# MM32SPIN0230 register map
Series: ARM Cortex M0; File version: 1.0
CPU: CM0 r0p0, little endian, no MPU, no FPU, 2 interrupt priority bits
Registers are 32-bit, read-write, reset 0x0 unless marked. A register's access mark holds for its fields unless they carry their own. Offsets are from the block's base; [hi:lo] are bit positions; {n}, {i} and the like mark numbered series.

## HWDIV
Base 0x40030000
0x00 DVDR — Dividend register
  [31:0] DIVIDEND
0x04 DVSR reset 0x1 — Divisor register
  [31:0] DIVISOR
0x08 QUOTR ro — Quotient register
  [31:0] QUOTIENT
0x0C RMDR ro — Remainder register
  [31:0] REMAINDER
0x10 SR ro — Status register
  [0] OVF
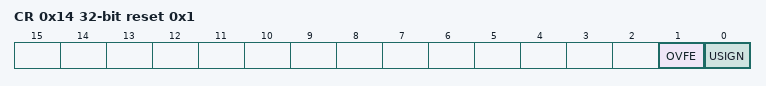
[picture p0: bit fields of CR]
0x14 CR reset 0x1 — Control register
  [1] OVFE, [0] USIGN

## IWDG
Base 0x40003000
0x00 KR wo — Key register
  [15:0] KEY
0x04 PR — Prescaler register
  [2:0] PR
0x08 RLR reset 0xFFF — Reload register
  [11:0] RL
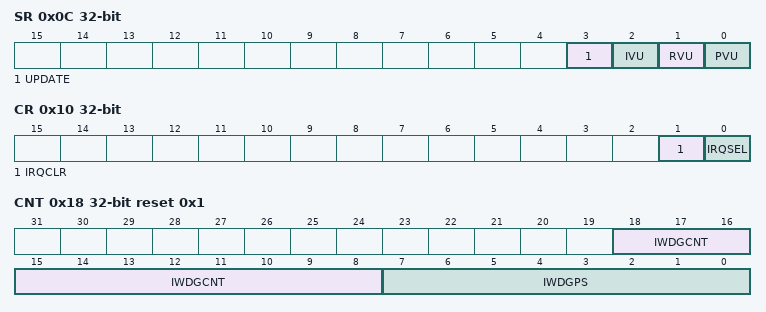
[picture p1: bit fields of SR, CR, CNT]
0x0C SR ro — Status register
  [3] UPDATE, [2] IVU, [1] RVU, [0] PVU
0x10 CR — Control register
  [1] IRQCLR, [0] IRQSEL
0x14 IGEN reset 0xFFF — Interrupt generate register
  [11:0] IGEN
0x18 CNT ro reset 0x1 — Counter register
  [18:8] IWDGCNT, [7:0] IWDGPS

## OPAMP1
Base 0x40009000
Same registers: OPAMP2 0x40009400
0x00 CR reset 0x2 — Configuration register
  [0] OPAEN

## PWR
Base 0x40007000
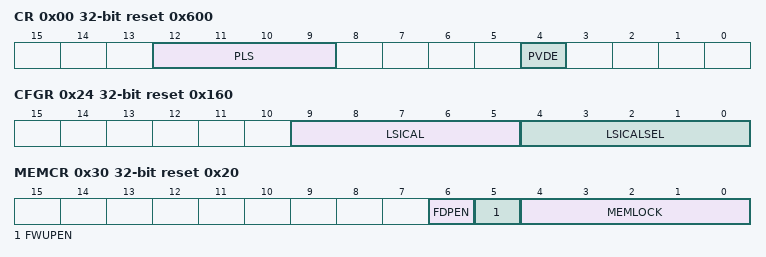
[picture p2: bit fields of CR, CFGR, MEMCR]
0x00 CR reset 0x600 — Power control register
  [12:9] PLS, [4] PVDE
0x04 CSR ro — Power control status register
  [2] PVDO
0x24 CFGR reset 0x160 — Power configuration register
  [9:5] LSICAL, [4:0] LSICALSEL wo
0x30 MEMCR reset 0x20 — Power memory control register
  [6] FDPEN, [5] FWUPEN, [4:0] MEMLOCK wo

## RCC
Base 0x40021000
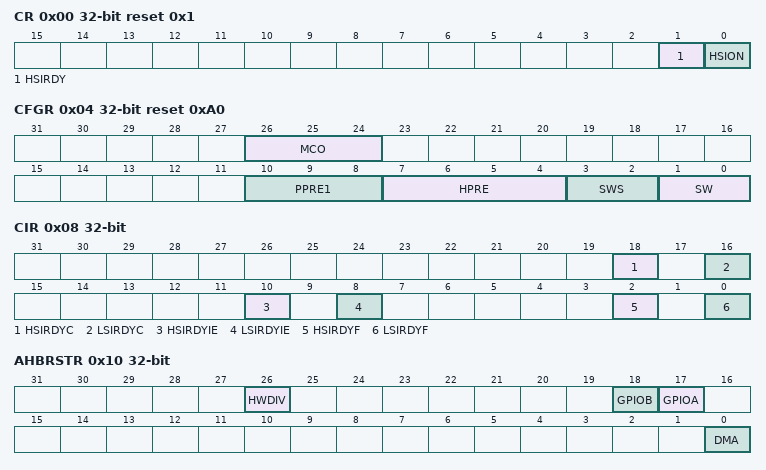
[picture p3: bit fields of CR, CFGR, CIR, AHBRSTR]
0x00 CR reset 0x1 — RCC control register
  [1] HSIRDY ro, [0] HSION
0x04 CFGR reset 0xA0 — RCC configuration register
  [26:24] MCO, [10:8] PPRE1, [7:4] HPRE, [3:2] SWS ro, [1:0] SW
0x08 CIR — RCC clock interrupt register
  [18] HSIRDYC write-1-clears, [16] LSIRDYC write-1-clears, [10] HSIRDYIE, [8] LSIRDYIE, [2] HSIRDYF ro, [0] LSIRDYF ro
0x10 AHBRSTR — RCC AHB peripheral reset register
  [26] HWDIV, [18] GPIOB, [17] GPIOA, [0] DMA
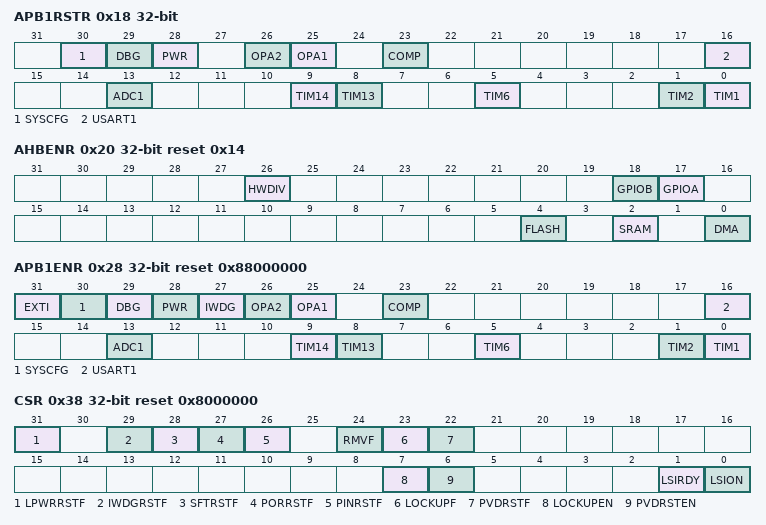
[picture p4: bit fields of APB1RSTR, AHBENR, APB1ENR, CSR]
0x18 APB1RSTR — RCC APB1 peripheral reset register
  [30] SYSCFG, [29] DBG, [28] PWR, [26] OPA2, [25] OPA1, [23] COMP, [16] USART1, [13] ADC1, [9] TIM14, [8] TIM13, [5] TIM6, [1] TIM2, [0] TIM1
0x20 AHBENR reset 0x14 — RCC AHB peripheral clock enable register
  [26] HWDIV, [18] GPIOB, [17] GPIOA, [4] FLASH, [2] SRAM, [0] DMA
0x28 APB1ENR reset 0x88000000 — RCC APB1 peripheral clock enable register
  [31] EXTI, [30] SYSCFG, [29] DBG, [28] PWR, [27] IWDG, [26] OPA2, [25] OPA1, [23] COMP, [16] USART1, [13] ADC1, [9] TIM14, [8] TIM13, [5] TIM6, [1] TIM2, [0] TIM1
0x38 CSR reset 0x8000000 — RCC control status register
  [31] LPWRRSTF ro, [29] IWDGRSTF ro, [28] SFTRSTF ro, [27] PORRSTF ro, [26] PINRSTF ro, [24] RMVF write-1-clears, [23] LOCKUPF ro, [22] PVDRSTF ro, [7] LOCKUPEN, [6] PVDRSTEN, [1] LSIRDY ro, [0] LSION

## SYSCFG
Base 0x40010000
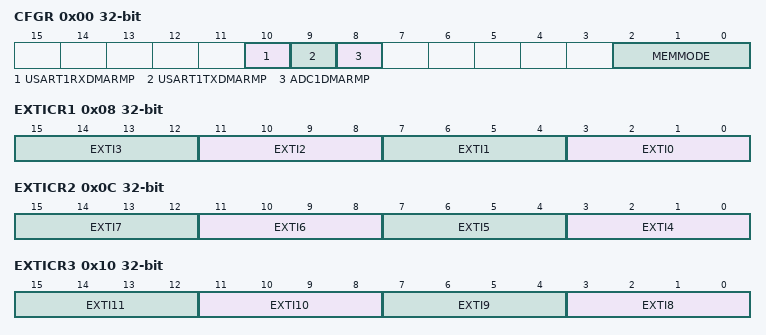
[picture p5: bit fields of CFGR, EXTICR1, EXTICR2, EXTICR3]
0x00 CFGR — SYSCFG configuration register
  [10] USART1RXDMARMP, [9] USART1TXDMARMP, [8] ADC1DMARMP, [2:0] MEMMODE
0x08 EXTICR1 — SYSCFG external interrupt configuration register 1
  [4n+3:4n] EXTI{n} (n=0..3)
0x0C EXTICR2 — SYSCFG external interrupt configuration register 2
  [4n-13:4n-16] EXTI{n} (n=4..7)
0x10 EXTICR3 — SYSCFG external interrupt configuration register 3
  [4n-29:4n-32] EXTI{n} (n=8..11)
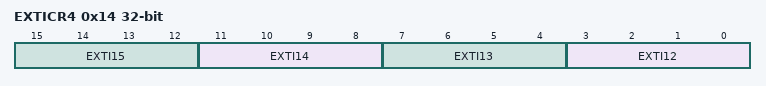
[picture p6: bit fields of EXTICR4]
0x14 EXTICR4 — SYSCFG external interrupt configuration register 4
  [4n-45:4n-48] EXTI{n} (n=12..15)

## TIM1
Base 0x40012C00
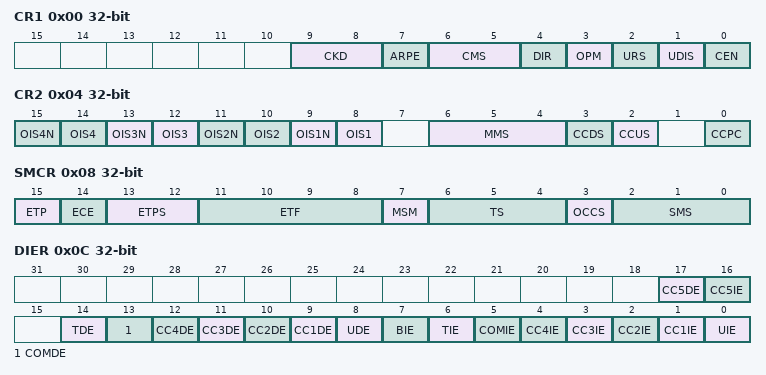
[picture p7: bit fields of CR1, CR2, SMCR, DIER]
0x00 CR1 — Control Register 1
  [9:8] CKD, [7] ARPE, [6:5] CMS, [4] DIR, [3] OPM, [2] URS, [1] UDIS, [0] CEN
0x04 CR2 — Control Register 2
  [2n+7] OIS{n}N (n=1..4), [2n+6] OIS{n} (n=1..4), [6:4] MMS, [3] CCDS, [2] CCUS, [0] CCPC
0x08 SMCR — Slave Mode Control Register
  [15] ETP, [14] ECE, [13:12] ETPS, [11:8] ETF, [7] MSM, [6:4] TS, [3] OCCS, [2:0] SMS
0x0C DIER — DMA/Interrupt Enable Register (DMA is only suitable for the chip with built in DMA)
  [17] CC5DE, [16] CC5IE, [14] TDE, [13] COMDE, [n+8] CC{n}DE (n=1..4), [8] UDE, [7] BIE, [6] TIE, [5] COMIE, [n] CC{n}IE (n=1..4), [0] UIE
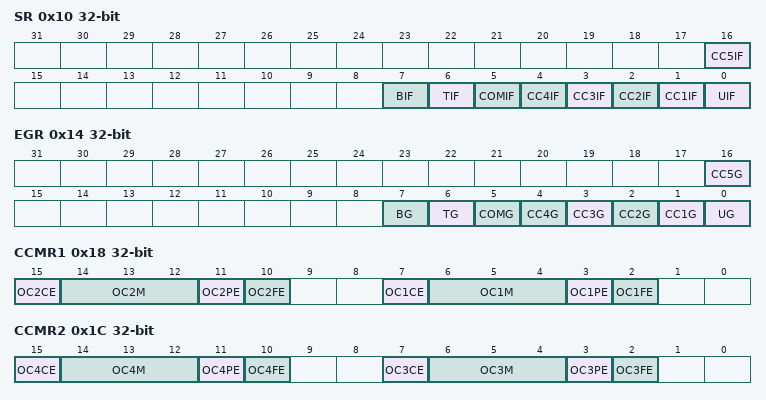
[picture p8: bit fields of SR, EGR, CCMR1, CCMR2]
0x10 SR — Status Register
  [16] CC5IF write-0-clears, [7] BIF write-0-clears, [6] TIF write-0-clears, [5] COMIF write-0-clears, [n] CC{n}IF write-0-clears (n=1..4), [0] UIF write-0-clears
0x14 EGR wo — Event Generation Register
  [16] CC5G, [7] BG, [6] TG, [5] COMG, [n] CC{n}G (n=1..4), [0] UG
0x18 CCMR1 — Compare Mode Register 1
  [15] OC2CE, [14:12] OC2M, [11] OC2PE, [10] OC2FE, [7] OC1CE, [6:4] OC1M, [3] OC1PE, [2] OC1FE
0x1C CCMR2 — Compare Mode Register 2
  [15] OC4CE, [14:12] OC4M, [11] OC4PE, [10] OC4FE, [7] OC3CE, [6:4] OC3M, [3] OC3PE, [2] OC3FE
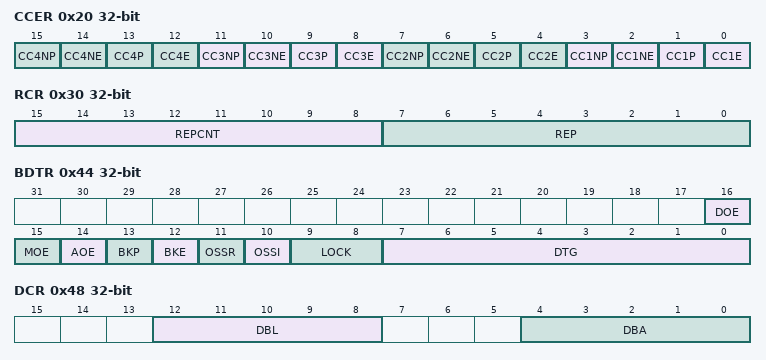
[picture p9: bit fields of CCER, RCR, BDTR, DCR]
0x20 CCER — Compare Enable Register
  [4n-1] CC{n}NP (n=1..4), [4n-2] CC{n}NE (n=1..4), [4n-3] CC{n}P (n=1..4), [4n-4] CC{n}E (n=1..4)
0x24 CNT — Counter
  [15:0] CNT
0x28 PSC — Prescaler
  [15:0] PSC
0x2C ARR — Auto Reload Register
  [15:0] ARR
0x30 RCR — Repeat Count Register
  [15:8] REPCNT, [7:0] REP
{0x30+4i} CCR{i} (i=1..4) — Compare Register {i}
  [15:0] CCR{i}
0x44 BDTR — Break And Dead-Time Register
  [16] DOE, [15] MOE, [14] AOE, [13] BKP, [12] BKE, [11] OSSR, [10] OSSI, [9:8] LOCK, [7:0] DTG
0x48 DCR — DMA Control Register (only suitable for the chip with built in DMA)
  [12:8] DBL, [4:0] DBA
0x4C DMAR wo — DMA Address Register Of Continuous Mode (only suitable for the chip with built in DMA)
  [15:0] DMAB
0x54 CCMR3 — Compare Mode Register 3
  [3] OC5PE
0x58 CCR5 — Compare Register 5
  [15:0] CCR5
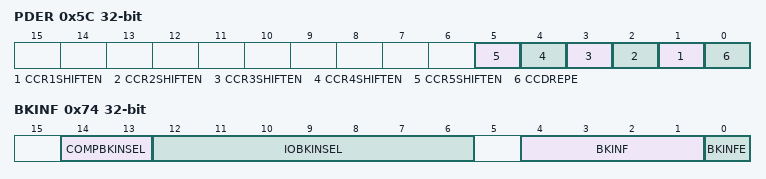
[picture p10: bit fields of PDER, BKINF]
0x5C PDER — PWM Phase Shift/DMA Repeat Update Request Enable Register
  [n] CCR{n}SHIFTEN (n=1..5), [0] CCDREPE
0x60 CCRxFALL — PWM Phase Shift Count Down Compare Register
  [15:0] CCRXFALL
{0x60+4i} CCRxFALL{i} (i=1..4) — PWM Phase Shift Count Down Compare Register
  [15:0] CCRXFALL
0x74 BKINF — Break Input Filter Register
  [14:13] COMPBKINSEL, [12:6] IOBKINSEL, [4:1] BKINF, [0] BKINFE
